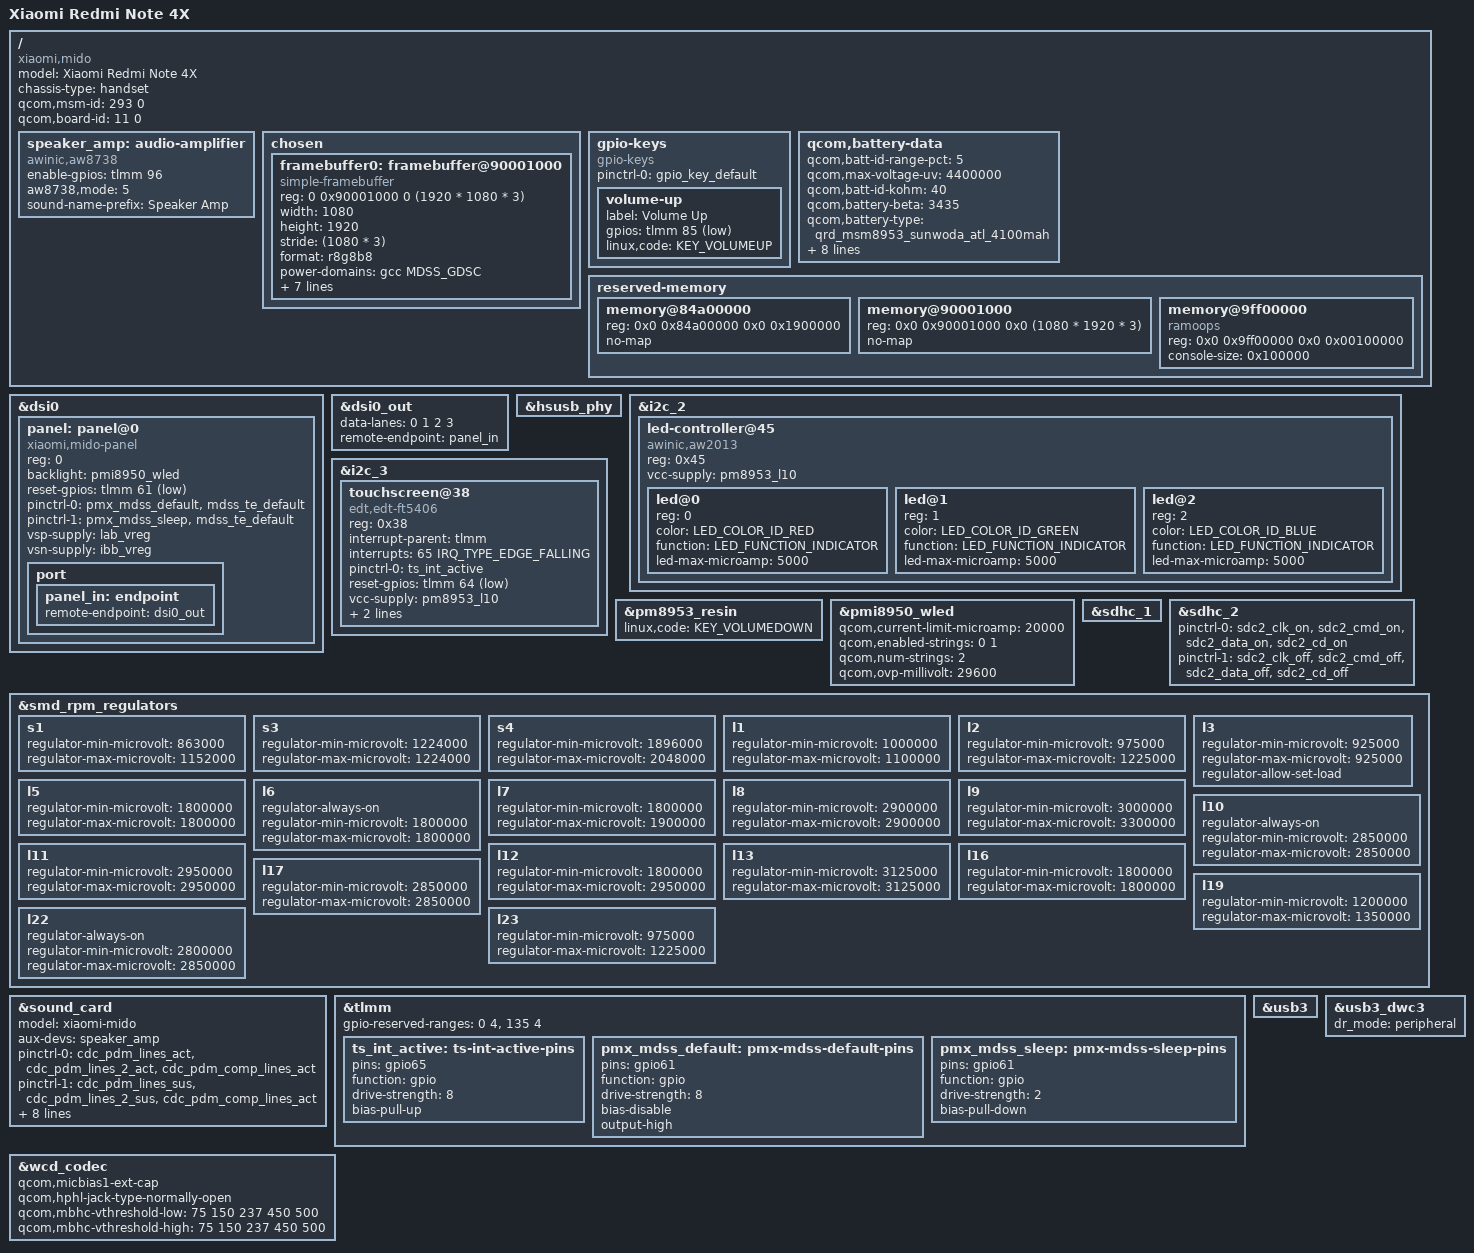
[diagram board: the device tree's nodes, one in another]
/* Copyright (c) 2022 The Linux Foundation. All rights reserved.
 *
 * This program is free software; you can redistribute it and/or modify
 * it under the terms of the GNU General Public License version 2 and
 * only version 2 as published by the Free Software Foundation.
 *
 * This program is distributed in the hope that it will be useful,
 * but WITHOUT ANY WARRANTY; without even the implied warranty of
 * MERCHANTABILITY or FITNESS FOR A PARTICULAR PURPOSE.  See the
 * GNU General Public License for more details.
 */
/dts-v1/;

#include "msm8953-pm8953.dtsi"
#include "pmi8950.dtsi"

#include <dt-bindings/leds/common.h>

/ {
	model = "Xiaomi Redmi Note 4X";
	compatible = "xiaomi,mido", "qcom,msm8953";
	chassis-type = "handset";
	qcom,msm-id = <293 0>;
	qcom,board-id = <11 0>;

	speaker_amp: audio-amplifier {
		compatible = "awinic,aw8738";

		enable-gpios = <&tlmm 96 GPIO_ACTIVE_HIGH>;
		aw8738,mode = <5>;
		sound-name-prefix = "Speaker Amp";
	};

	chosen {
		#address-cells = <2>;
		#size-cells = <2>;
		ranges;

		framebuffer0: framebuffer@90001000 {
			compatible = "simple-framebuffer";
			reg = <0 0x90001000 0 (1920 * 1080 * 3)>;

			width = <1080>;
			height = <1920>;
			stride = <(1080 * 3)>;
			format = "r8g8b8";

			power-domains = <&gcc MDSS_GDSC>;

			clocks = <&gcc GCC_MDSS_AHB_CLK>,
				 <&gcc GCC_MDSS_AXI_CLK>,
				 <&gcc GCC_MDSS_VSYNC_CLK>,
				 <&gcc GCC_MDSS_MDP_CLK>,
				 <&gcc GCC_MDSS_BYTE0_CLK>,
				 <&gcc GCC_MDSS_PCLK0_CLK>,
				 <&gcc GCC_MDSS_ESC0_CLK>;
		};
	};

	gpio-keys {
		compatible = "gpio-keys";

		pinctrl-names = "default";
		pinctrl-0 = <&gpio_key_default>;

		volume-up {
			label = "Volume Up";
			gpios = <&tlmm 85 GPIO_ACTIVE_LOW>;
			linux,code = <KEY_VOLUMEUP>;
		};
	};

	qcom,battery-data {
		qcom,batt-id-range-pct = <5>;
		qcom,max-voltage-uv = <4400000>;
		qcom,batt-id-kohm = <40>;
		qcom,battery-beta = <3435>;
		qcom,battery-type = "qrd_msm8953_sunwoda_atl_4100mah";
		qcom,chg-rslow-comp-c1 = <3159320>;
		qcom,chg-rslow-comp-c2 = <4074348>;
		qcom,chg-rs-to-rslow = <921524>;
		qcom,chg-rslow-comp-thr = <0x9C>;
		qcom,checksum = <0xDC57>;
		qcom,thermal-coefficients = [c8 86 c1 50 d3 37];
		qcom,fg-profile-data = [ DC 83 9E 7C
					 CD 80 80 76
					 60 83 FD 6E
					 04 89 50 94
					 38 82 24 99
					 C7 B7 F4 C3
					 56 0F 06 88
					 F9 7D BA 81
					 0F 7C 54 83
					 B3 69 2B 7A
					 FE 87 4B 82
					 DA 99 33 BD
					 45 CA 58 0D
					 13 10 39 58
					 14 70 DA FC
					 3A 36 CF 46
					 1E 42 00 00
					 5D 46 C4 3B
					 0A 44 00 00
					 00 00 00 00
					 00 00 00 00
					 AD 72 EE 70
					 73 58 12 88
					 E9 75 4D 68
					 47 61 B0 7A
					 24 74 10 53
					 19 74 5B AA
					 23 44 69 3E
					 67 A0 71 0C
					 28 00 FF 36
					 F0 11 30 03
					 00 00 00 0C ];
	};

	reserved-memory {
		/delete-node/memory@85b00000;

		memory@84a00000 {
			reg = <0x0 0x84a00000 0x0 0x1900000>;
			no-map;
		};

		memory@90001000 {
			reg = <0x0 0x90001000 0x0 (1080 * 1920 * 3)>;
			no-map;
		};

		memory@9ff00000 {
			compatible = "ramoops";
			reg = <0x0 0x9ff00000 0x0 0x00100000>;
			console-size = <0x100000>;
		};
	};
};

&dsi0 {
	panel: panel@0 {
		compatible = "xiaomi,mido-panel";
		reg = <0>;

		backlight = <&pmi8950_wled>;

		reset-gpios = <&tlmm 61 GPIO_ACTIVE_LOW>;

		pinctrl-names = "default", "sleep";
		pinctrl-0 = <&pmx_mdss_default &mdss_te_default>;
		pinctrl-1 = <&pmx_mdss_sleep &mdss_te_default>;

		vsp-supply = <&lab_vreg>;
		vsn-supply = <&ibb_vreg>;

		port {
			panel_in: endpoint {
				remote-endpoint = <&dsi0_out>;
			};
		};
	};
};

&dsi0_out {
	data-lanes = <0 1 2 3>;
	remote-endpoint = <&panel_in>;
};

&hsusb_phy {
	status = "okay";
};

&i2c_2 {
	status = "okay";

	led-controller@45 {
		compatible = "awinic,aw2013";
		reg = <0x45>;

		vcc-supply = <&pm8953_l10>;

		#address-cells = <1>;
		#size-cells = <0>;

		led@0 {
			reg = <0>;
			color = <LED_COLOR_ID_RED>;
			function = LED_FUNCTION_INDICATOR;
			led-max-microamp = <5000>;
		};

		led@1 {
			reg = <1>;
			color = <LED_COLOR_ID_GREEN>;
			function = LED_FUNCTION_INDICATOR;
			led-max-microamp = <5000>;
		};

		led@2 {
			reg = <2>;
			color = <LED_COLOR_ID_BLUE>;
			function = LED_FUNCTION_INDICATOR;
			led-max-microamp = <5000>;
		};
	};
};

&i2c_3 {
	status = "okay";

	touchscreen@38 {
		compatible = "edt,edt-ft5406", "edt,edt-ft5x06";
		reg = <0x38>;

		interrupt-parent = <&tlmm>;
		interrupts = <65 IRQ_TYPE_EDGE_FALLING>;

		pinctrl-names = "default";
		pinctrl-0 = <&ts_int_active>;

		reset-gpios = <&tlmm 64 GPIO_ACTIVE_LOW>;

		vcc-supply = <&pm8953_l10>;

		touchscreen-size-x = <1080>;
		touchscreen-size-y = <1920>;
	};
};

&pm8953_resin {
	status = "okay";
	linux,code = <KEY_VOLUMEDOWN>;
};

&pmi8950_wled {
	status = "okay";

	/* Don't copy-paste! See pmi8950.dtsi */

	qcom,current-limit-microamp = <20000>;
	qcom,enabled-strings = <0 1>;
	qcom,num-strings = <2>;
	qcom,ovp-millivolt = <29600>;
};

&sdhc_1 {
	status = "okay";
};

&sdhc_2 {
	status = "okay";

	pinctrl-names = "default", "sleep";
	pinctrl-0 = <&sdc2_clk_on &sdc2_cmd_on &sdc2_data_on &sdc2_cd_on>;
	pinctrl-1 = <&sdc2_clk_off &sdc2_cmd_off &sdc2_data_off &sdc2_cd_off>;

	// cd-gpios = <&tlmm 133 GPIO_ACTIVE_LOW>;
};

&smd_rpm_regulators {
	// TODO Add supplies

	s1 {
		regulator-min-microvolt = <863000>;
		regulator-max-microvolt = <1152000>;
	};

	s3 {
		regulator-min-microvolt = <1224000>;
		regulator-max-microvolt = <1224000>;
	};

	s4 {
		regulator-min-microvolt = <1896000>;
		regulator-max-microvolt = <2048000>;
	};

	l1 {
		regulator-min-microvolt = <1000000>;
		regulator-max-microvolt = <1100000>;
	};

	l2 {
		regulator-min-microvolt = <975000>;
		regulator-max-microvolt = <1225000>;
	};

	l3 {
		regulator-min-microvolt = <925000>;
		regulator-max-microvolt = <925000>;
		regulator-allow-set-load;
	};

	l5 {
		regulator-min-microvolt = <1800000>;
		regulator-max-microvolt = <1800000>;
	};

	l6 {
		regulator-always-on;
		regulator-min-microvolt = <1800000>;
		regulator-max-microvolt = <1800000>;
	};

	l7 {
		regulator-min-microvolt = <1800000>;
		regulator-max-microvolt = <1900000>;
	};

	l8 {
		regulator-min-microvolt = <2900000>;
		regulator-max-microvolt = <2900000>;
	};

	l9 {
		regulator-min-microvolt = <3000000>;
		regulator-max-microvolt = <3300000>;
	};

	l10 {
		regulator-always-on;
		regulator-min-microvolt = <2850000>;
		regulator-max-microvolt = <2850000>;
	};

	l11 {
		regulator-min-microvolt = <2950000>;
		regulator-max-microvolt = <2950000>;
	};

	l12 {
		regulator-min-microvolt = <1800000>;
		regulator-max-microvolt = <2950000>;
	};

	l13 {
		regulator-min-microvolt = <3125000>;
		regulator-max-microvolt = <3125000>;
	};

	l16 {
		regulator-min-microvolt = <1800000>;
		regulator-max-microvolt = <1800000>;
	};

	l17 {
		regulator-min-microvolt = <2850000>;
		regulator-max-microvolt = <2850000>;
	};

	l19 {
		regulator-min-microvolt = <1200000>;
		regulator-max-microvolt = <1350000>;
	};

	l22 {
		regulator-always-on;
		regulator-min-microvolt = <2800000>;
		regulator-max-microvolt = <2850000>;
	};

	l23 {
		regulator-min-microvolt = <975000>;
		regulator-max-microvolt = <1225000>;
	};
};

&sound_card {
	status = "okay";

	model = "xiaomi-mido";

	aux-devs = <&speaker_amp>;

	pinctrl-names = "default", "sleep";
	pinctrl-0 = <&cdc_pdm_lines_act &cdc_pdm_lines_2_act &cdc_pdm_comp_lines_act>;
	pinctrl-1 = <&cdc_pdm_lines_sus &cdc_pdm_lines_2_sus &cdc_pdm_comp_lines_act>;

	/delete-property/ audio-routing;
	audio-routing =
		"Speaker Amp IN", "LINEOUT_OUT",
		"AMIC1", "MIC BIAS External1",
		"AMIC2", "MIC BIAS Internal2",
		"AMIC3", "MIC BIAS External1",
		"MM_DL1", "MultiMedia1 Playback",
		"MM_DL3", "MultiMedia3 Playback",
		"MM_DL4", "MultiMedia4 Playback",
		"MultiMedia2 Capture", "MM_UL2";
};

&tlmm {
	gpio-reserved-ranges = <0 4>, <135 4>;

	ts_int_active: ts-int-active-pins {
		pins = "gpio65";
		function = "gpio";
		drive-strength = <8>;
		bias-pull-up;
	};

	pmx_mdss_default: pmx-mdss-default-pins {
		pins = "gpio61";
		function = "gpio";
		drive-strength = <8>;
		bias-disable;
		output-high;
	};

	pmx_mdss_sleep: pmx-mdss-sleep-pins {
		pins = "gpio61";
		function = "gpio";
		drive-strength = <2>;
		bias-pull-down;
	};
};

&usb3 {
	status = "okay";
};

&usb3_dwc3 {
	dr_mode = "peripheral";
};

&wcd_codec {
	qcom,micbias1-ext-cap;
	qcom,hphl-jack-type-normally-open;
	qcom,mbhc-vthreshold-low = <75 150 237 450 500>;
	qcom,mbhc-vthreshold-high = <75 150 237 450 500>;
};
